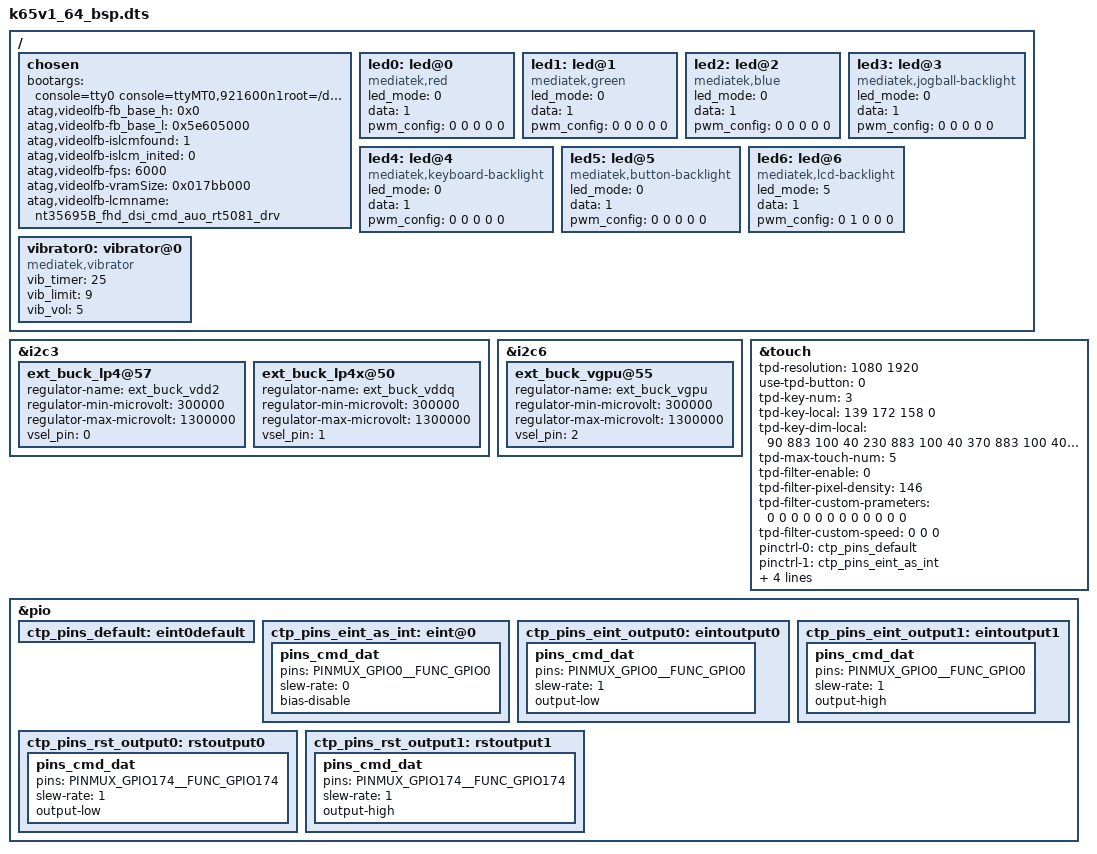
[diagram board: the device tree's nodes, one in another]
/dts-v1/;

#include "mt6765.dts"

/ {

	/* chosen */
	chosen {
		bootargs = "console=tty0 console=ttyMT0,921600n1\
root=/dev/ram initrd=0x45000000,0x1000000 loglevel=8 \
androidboot.selinux=permissive androidboot.hardware=mt6765 \
initcall_debug=1 maxcpus=1";

		/* fpga may has no lk, we need to specify display info here */
		/* fb buffer is reserved using this dts by memory node above */
		atag,videolfb-fb_base_h = <0x0>;
		atag,videolfb-fb_base_l = <0x5e605000>;
		atag,videolfb-islcmfound = <1>;
		/* because no lk, so lcm is not inited */
		atag,videolfb-islcm_inited = <0>;
		atag,videolfb-fps= <6000>;
		atag,videolfb-vramSize= <0x017bb000>;
		atag,videolfb-lcmname= "nt35695B_fhd_dsi_cmd_auo_rt5081_drv";
	};

	led0:led@0 {
		compatible = "mediatek,red";
		led_mode = <0>;
		data = <1>;
		pwm_config = <0 0 0 0 0>;
	};
	led1:led@1 {
		compatible = "mediatek,green";
		led_mode = <0>;
		data = <1>;
		pwm_config = <0 0 0 0 0>;
	};
	led2:led@2 {
		compatible = "mediatek,blue";
		led_mode = <0>;
		data = <1>;
		pwm_config = <0 0 0 0 0>;
	};
	led3:led@3 {
		compatible = "mediatek,jogball-backlight";
		led_mode = <0>;
		data = <1>;
		pwm_config = <0 0 0 0 0>;
	};
	led4:led@4 {
		compatible = "mediatek,keyboard-backlight";
		led_mode = <0>;
		data = <1>;
		pwm_config = <0 0 0 0 0>;
	};
	led5:led@5 {
		compatible = "mediatek,button-backlight";
		led_mode = <0>;
		data = <1>;
		pwm_config = <0 0 0 0 0>;
	};
	led6:led@6 {
		compatible = "mediatek,lcd-backlight";
		led_mode = <5>;
		data = <1>;
		pwm_config = <0 1 0 0 0>;
	};
	vibrator0:vibrator@0 {
		compatible = "mediatek,vibrator";
		vib_timer = <25>;
		vib_limit = <9>;
		vib_vol= <5>;
	};
};

&i2c3 {
	ext_buck_lp4@57 {
		regulator-name ="ext_buck_vdd2";
		regulator-min-microvolt = <300000>;
		regulator-max-microvolt = <1300000>;
		vsel_pin = <0>;
	};

	ext_buck_lp4x@50 {
		regulator-name ="ext_buck_vddq";
		regulator-min-microvolt = <300000>;
		regulator-max-microvolt = <1300000>;
		vsel_pin = <1>;
	};
};

&i2c6 {
	ext_buck_vgpu@55 {
		regulator-name ="ext_buck_vgpu";
		regulator-min-microvolt = <300000>;
		regulator-max-microvolt = <1300000>;
		vsel_pin = <2>;
	};
};
/* TOUCH start */
&touch {
	tpd-resolution = <1080 1920>;
	use-tpd-button = <0>;
	tpd-key-num = <3>;
	tpd-key-local= <139 172 158 0>;
	tpd-key-dim-local = <90 883 100 40 230
				 883 100 40 370 883 100 40 0 0 0 0>;
	tpd-max-touch-num = <5>;
	tpd-filter-enable = <0>;
	tpd-filter-pixel-density = <146>;
	tpd-filter-custom-prameters = <0 0 0 0 0 0 0 0 0 0 0 0>;
	tpd-filter-custom-speed = <0 0 0>;
	pinctrl-names = "default", "state_eint_as_int", "state_eint_output0",
		"state_eint_output1", "state_rst_output0", "state_rst_output1";
	pinctrl-0 = <&ctp_pins_default>;
	pinctrl-1 = <&ctp_pins_eint_as_int>;
	pinctrl-2 = <&ctp_pins_eint_output0>;
	pinctrl-3 = <&ctp_pins_eint_output1>;
	pinctrl-4 = <&ctp_pins_rst_output0>;
	pinctrl-5 = <&ctp_pins_rst_output1>;
	status = "okay";
};
&pio {
	ctp_pins_default: eint0default {
	};
	ctp_pins_eint_as_int: eint@0 {
		pins_cmd_dat {
			pins = <PINMUX_GPIO0__FUNC_GPIO0>;
			slew-rate = <0>;
			bias-disable;
		};
	};
	ctp_pins_eint_output0: eintoutput0 {
		pins_cmd_dat {
			pins = <PINMUX_GPIO0__FUNC_GPIO0>;
			slew-rate = <1>;
			output-low;
		};
	};
	ctp_pins_eint_output1: eintoutput1 {
		pins_cmd_dat {
			pins = <PINMUX_GPIO0__FUNC_GPIO0>;
			slew-rate = <1>;
			output-high;
		};
	};
	ctp_pins_rst_output0: rstoutput0 {
		pins_cmd_dat {
			pins = <PINMUX_GPIO174__FUNC_GPIO174>;
			slew-rate = <1>;
			output-low;
		};
	};
	ctp_pins_rst_output1: rstoutput1 {
		pins_cmd_dat {
			pins = <PINMUX_GPIO174__FUNC_GPIO174>;
			slew-rate = <1>;
			output-high;
		};
	};
};
/* TOUCH end */

